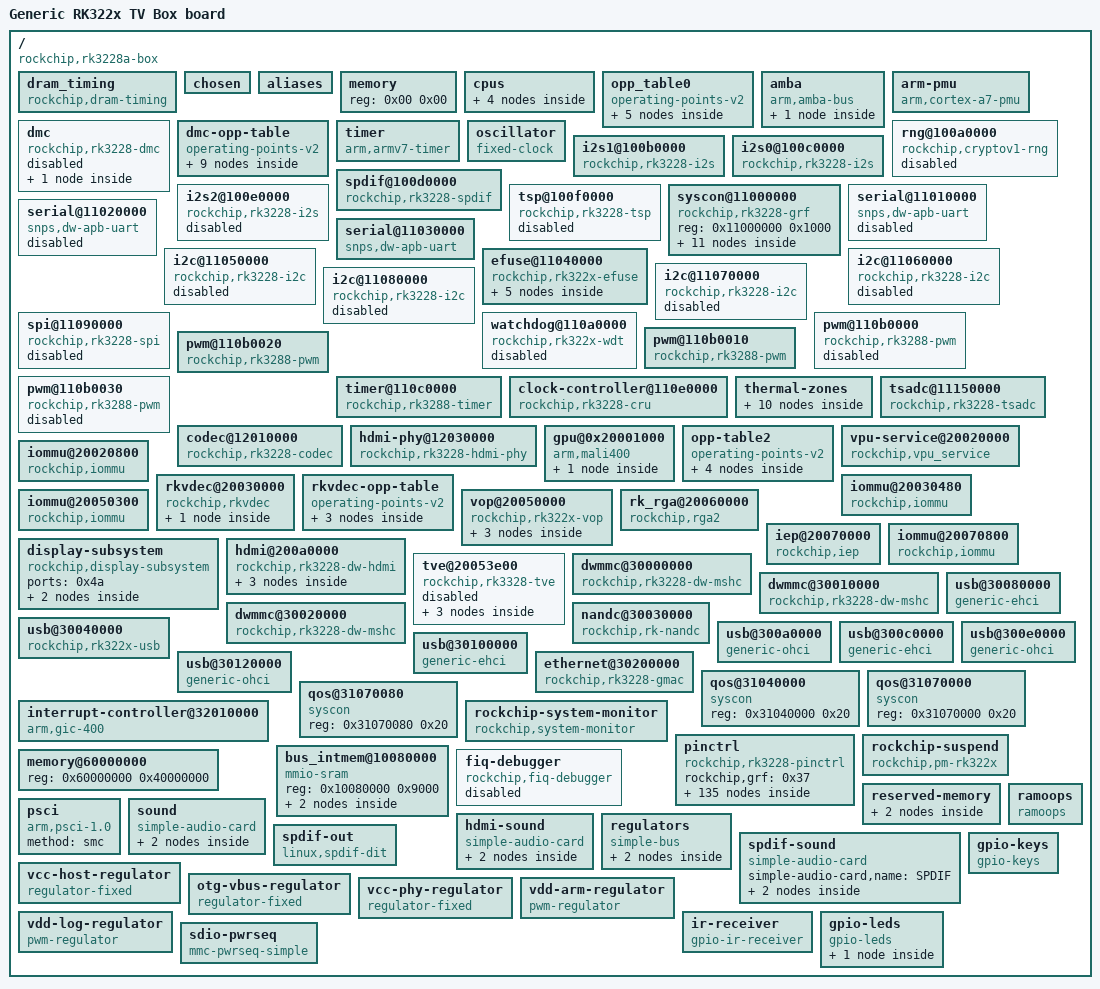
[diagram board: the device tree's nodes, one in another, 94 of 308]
/dts-v1/;

/ {
	#address-cells = <0x01>;
	#size-cells = <0x01>;
	interrupt-parent = <0x01>;
	compatible = "rockchip,rk3228a-box\0rockchip,rk3229";
	model = "Generic RK322x TV Box board";

	dram_timing {
		compatible = "rockchip,dram-timing";
		dram_spd_bin = <0x15>;
		sr_idle = <0x18>;
		pd_idle = <0x20>;
		dram_dll_disb_freq = <0x12c>;
		phy_dll_disb_freq = <0x190>;
		dram_odt_disb_freq = <0x14d>;
		phy_odt_disb_freq = <0x14d>;
		ddr3_drv = <0x00>;
		ddr3_odt = <0x40>;
		lpddr3_drv = <0x01>;
		lpddr3_odt = <0x03>;
		lpddr2_drv = <0x01>;
		phy_ddr3_clk_drv = <0x12>;
		phy_ddr3_cmd_drv = <0x12>;
		phy_ddr3_dqs_drv = <0x15>;
		phy_ddr3_odt = <0x02>;
		phy_lp23_clk_drv = <0x13>;
		phy_lp23_cmd_drv = <0x16>;
		phy_lp23_dqs_drv = <0x16>;
		phy_lp3_odt = <0x02>;
		phandle = <0x0b>;
	};

	chosen {
		stdout-path = "/serial@11030000";
		bootargs = "earlycon=uart8250,mmio32,0x11030000";
	};

	aliases {
		serial0 = "/serial@11010000";
		serial1 = "/serial@11020000";
		serial2 = "/serial@11030000";
		spi0 = "/spi@11090000";
	};

	memory {
		device_type = "memory";
		reg = <0x00 0x00>;
	};

	cpus {
		#address-cells = <0x01>;
		#size-cells = <0x00>;

		cpu@f00 {
			device_type = "cpu";
			compatible = "arm,cortex-a7";
			reg = <0xf00>;
			resets = <0x02 0x04>;
			operating-points-v2 = <0x03>;
			#cooling-cells = <0x02>;
			dynamic-power-coefficient = <0x7a>;
			clock-latency = <0x9c40>;
			clocks = <0x02 0x05>;
			enable-method = "psci";
			cpu-supply = <0x04>;
			phandle = <0x06>;
		};

		cpu@f01 {
			device_type = "cpu";
			compatible = "arm,cortex-a7";
			reg = <0xf01>;
			resets = <0x02 0x05>;
			operating-points-v2 = <0x03>;
			enable-method = "psci";
			cpu-supply = <0x04>;
			phandle = <0x07>;
		};

		cpu@f02 {
			device_type = "cpu";
			compatible = "arm,cortex-a7";
			reg = <0xf02>;
			resets = <0x02 0x06>;
			operating-points-v2 = <0x03>;
			enable-method = "psci";
			cpu-supply = <0x04>;
			phandle = <0x08>;
		};

		cpu@f03 {
			device_type = "cpu";
			compatible = "arm,cortex-a7";
			reg = <0xf03>;
			resets = <0x02 0x07>;
			operating-points-v2 = <0x03>;
			enable-method = "psci";
			cpu-supply = <0x04>;
			phandle = <0x09>;
		};
	};

	opp_table0 {
		compatible = "operating-points-v2";
		opp-shared;
		clocks = <0x02 0x01>;
		rockchip,max-volt = <0x149970>;
		rockchip,leakage-voltage-sel = <0x01 0x08 0x00 0x09 0xfe 0x01>;
		nvmem-cells = <0x05>;
		nvmem-cell-names = "cpu_leakage";
		phandle = <0x03>;

		opp-408000000 {
			opp-hz = <0x00 0x18519600>;
			opp-microvolt = <0xe7ef0 0xe7ef0 0x155cc0>;
			opp-microvolt-L0 = <0xe7ef0 0xe7ef0 0x155cc0>;
			opp-microvolt-L1 = <0xe7ef0 0xe7ef0 0x155cc0>;
			clock-latency-ns = <0x9c40>;
			opp-suspend;
		};

		opp-600000000 {
			opp-hz = <0x00 0x23c34600>;
			opp-microvolt = <0xee098 0xee098 0x155cc0>;
			opp-microvolt-L0 = <0xee098 0xee098 0x155cc0>;
			opp-microvolt-L1 = <0xee098 0xee098 0x155cc0>;
		};

		opp-816000000 {
			opp-hz = <0x00 0x30a32c00>;
			opp-microvolt = <0xf4240 0xf4240 0x155cc0>;
			opp-microvolt-L0 = <0xf4240 0xf4240 0x155cc0>;
			opp-microvolt-L1 = <0xf4240 0xf4240 0x155cc0>;
		};

		opp-1008000000 {
			opp-hz = <0x00 0x3c14dc00>;
			opp-microvolt = <0x11edd8 0x11edd8 0x155cc0>;
			opp-microvolt-L0 = <0x11edd8 0x11edd8 0x155cc0>;
			opp-microvolt-L1 = <0x112a88 0x112a88 0x155cc0>;
		};

		opp-1200000000 {
			opp-hz = <0x00 0x47868c00>;
			opp-microvolt = <0x137478 0x137478 0x155cc0>;
			opp-microvolt-L0 = <0x137478 0x137478 0x155cc0>;
			opp-microvolt-L1 = <0x12b128 0x12b128 0x155cc0>;
		};
	};

	amba {
		compatible = "arm,amba-bus";
		#address-cells = <0x01>;
		#size-cells = <0x01>;
		ranges;

		pdma@110f0000 {
			compatible = "arm,pl330\0arm,primecell";
			reg = <0x110f0000 0x4000>;
			interrupts = <0x00 0x00 0x04 0x00 0x01 0x04>;
			#dma-cells = <0x01>;
			clocks = <0x02 0xc2>;
			clock-names = "apb_pclk";
			peripherals-req-type-burst;
			phandle = <0x0e>;
		};
	};

	arm-pmu {
		compatible = "arm,cortex-a7-pmu";
		interrupts = <0x00 0x4c 0x04 0x00 0x4d 0x04 0x00 0x4e 0x04 0x00 0x4f 0x04>;
		interrupt-affinity = <0x06 0x07 0x08 0x09>;
	};

	dmc {
		compatible = "rockchip,rk3228-dmc\0rockchip,rk322x-dram";
		clocks = <0x02 0x90>;
		clock-names = "dmc_clk";
		operating-points-v2 = <0x0a>;
		system-status-freq = <0x01 0x927c0 0x10 0xa2990 0x10000 0xbfe50>;
		dram_freq = <0x2ed96880>;
		rockchip,dram_timing = <0x0b>;
		#cooling-cells = <0x02>;
		status = "disabled";
		center-supply = <0x0c>;
		phandle = <0x3b>;

		ddr_power_model {
			compatible = "ddr_power_model";
			dynamic-power-coefficient = <0x78>;
			static-power-coefficient = <0xc8>;
			ts = <0x7d00 0x125c 0xffffffb0 0x02>;
			thermal-zone = "soc-thermal";
			phandle = <0x78>;
		};
	};

	dmc-opp-table {
		compatible = "operating-points-v2";
		rockchip,leakage-voltage-sel = <0x01 0x05 0x00 0x06 0xfe 0x01>;
		nvmem-cells = <0x0d>;
		nvmem-cell-names = "ddr_leakage";
		phandle = <0x0a>;

		opp-300000000 {
			opp-hz = <0x00 0x11e1a300>;
			opp-microvolt = <0x100590>;
			opp-microvolt-L0 = <0x100590>;
			opp-microvolt-L1 = <0xf4240>;
		};

		opp-330000000 {
			opp-hz = <0x00 0x13ab6680>;
			opp-microvolt = <0x100590>;
			opp-microvolt-L0 = <0x100590>;
			opp-microvolt-L1 = <0xf4240>;
		};

		opp-400000000 {
			opp-hz = <0x00 0x17d78400>;
			opp-microvolt = <0x100590>;
			opp-microvolt-L0 = <0x100590>;
			opp-microvolt-L1 = <0xf4240>;
		};

		opp-528000000 {
			opp-hz = <0x00 0x1f78a400>;
			opp-microvolt = <0x100590>;
			opp-microvolt-L0 = <0x100590>;
			opp-microvolt-L1 = <0xf4240>;
		};

		opp-600000000 {
			opp-hz = <0x00 0x23c34600>;
			opp-microvolt = <0x10c8e0>;
			opp-microvolt-L0 = <0x10c8e0>;
			opp-microvolt-L1 = <0x100590>;
		};

		opp-666000000 {
			opp-hz = <0x00 0x27b25a80>;
			opp-microvolt = <0x118c30>;
			opp-microvolt-L0 = <0x118c30>;
			opp-microvolt-L1 = <0x10c8e0>;
		};

		opp-700000000 {
			opp-hz = <0x00 0x29b92700>;
			opp-microvolt = <0x118c30>;
			opp-microvolt-L0 = <0x118c30>;
			opp-microvolt-L1 = <0x10c8e0>;
		};

		opp-786000000 {
			opp-hz = <0x00 0x2ed96880>;
			opp-microvolt = <0x118c30>;
			opp-microvolt-L0 = <0x118c30>;
			opp-microvolt-L1 = <0x10c8e0>;
		};

		opp-800000000 {
			opp-hz = <0x00 0x2faf0800>;
			opp-microvolt = <0x118c30>;
			opp-microvolt-L0 = <0x118c30>;
			opp-microvolt-L1 = <0x10c8e0>;
		};
	};

	timer {
		compatible = "arm,armv7-timer";
		interrupts = <0x01 0x0d 0xf04 0x01 0x0e 0xf04 0x01 0x0b 0xf04 0x01 0x0a 0xf04>;
		clock-frequency = <0x16e3600>;
		arm,cpu-registers-not-fw-configured;
	};

	oscillator {
		compatible = "fixed-clock";
		clock-frequency = <0x16e3600>;
		clock-output-names = "xin24m";
		#clock-cells = <0x00>;
		phandle = <0x36>;
	};

	rng@100a0000 {
		compatible = "rockchip,cryptov1-rng";
		reg = <0x100a0000 0x4000>;
		clocks = <0x02 0x8a 0x02 0x1dd>;
		clock-names = "clk_crypto\0hclk_crypto";
		assigned-clocks = <0x02 0x8a 0x02 0x1dd>;
		assigned-clock-rates = <0x8f0d180 0x5f5e100>;
		resets = <0x02 0x35>;
		reset-names = "reset";
		status = "disabled";
		phandle = <0x79>;
	};

	i2s1@100b0000 {
		compatible = "rockchip,rk3228-i2s\0rockchip,rk3066-i2s";
		reg = <0x100b0000 0x4000>;
		interrupts = <0x00 0x1b 0x04>;
		#address-cells = <0x01>;
		#size-cells = <0x00>;
		clock-names = "i2s_clk\0i2s_hclk";
		clocks = <0x02 0x51 0x02 0x1bb>;
		dmas = <0x0e 0x0e 0x0e 0x0f>;
		dma-names = "tx\0rx";
		resets = <0x02 0x19>;
		reset-names = "reset-m";
		pinctrl-names = "default";
		pinctrl-0 = <0x0f>;
		status = "okay";
		#sound-dai-cells = <0x00>;
		phandle = <0x6a>;
	};

	i2s0@100c0000 {
		compatible = "rockchip,rk3228-i2s\0rockchip,rk3066-i2s";
		reg = <0x100c0000 0x4000>;
		interrupts = <0x00 0x1a 0x04>;
		#address-cells = <0x01>;
		#size-cells = <0x00>;
		clock-names = "i2s_clk\0i2s_hclk";
		clocks = <0x02 0x50 0x02 0x1ba>;
		dmas = <0x0e 0x0b 0x0e 0x0c>;
		dma-names = "tx\0rx";
		resets = <0x02 0x18>;
		reset-names = "reset-m";
		status = "okay";
		rockchip,bclk-fs = <0x80>;
		#sound-dai-cells = <0x00>;
		phandle = <0x6c>;
	};

	spdif@100d0000 {
		compatible = "rockchip,rk3228-spdif";
		reg = <0x100d0000 0x1000>;
		interrupts = <0x00 0x1d 0x04>;
		clocks = <0x02 0x53 0x02 0x1bd>;
		clock-names = "mclk\0hclk";
		dmas = <0x0e 0x0a>;
		#dma-cells = <0x01>;
		dma-names = "tx";
		pinctrl-names = "default";
		pinctrl-0 = <0x10>;
		status = "okay";
		#sound-dai-cells = <0x00>;
		phandle = <0x6e>;
	};

	i2s2@100e0000 {
		compatible = "rockchip,rk3228-i2s\0rockchip,rk3066-i2s";
		reg = <0x100e0000 0x4000>;
		interrupts = <0x00 0x1c 0x04>;
		#address-cells = <0x01>;
		#size-cells = <0x00>;
		clock-names = "i2s_clk\0i2s_hclk";
		clocks = <0x02 0x52 0x02 0x1bc>;
		dmas = <0x0e 0x00 0x0e 0x01>;
		dma-names = "tx\0rx";
		resets = <0x02 0x1a>;
		reset-names = "reset-m";
		status = "disabled";
		phandle = <0x7a>;
	};

	tsp@100f0000 {
		compatible = "rockchip,rk3228-tsp";
		reg = <0x100f0000 0x10000>;
		interrupts = <0x00 0x48 0x04>;
		interrupt-names = "irq_tsp";
		clocks = <0x02 0x8b 0x02 0x1db 0x02 0x8c>;
		clock-names = "clk_tsp\0hclk_tsp\0aclk_tsp";
		pinctrl-names = "default";
		pinctrl-0 = <0x11 0x12 0x13 0x14 0x15 0x16 0x17 0x18 0x19 0x1a 0x1b 0x1c>;
		status = "disabled";
		phandle = <0x7b>;
	};

	syscon@11000000 {
		compatible = "rockchip,rk3228-grf\0syscon\0simple-mfd";
		reg = <0x11000000 0x1000>;
		#address-cells = <0x01>;
		#size-cells = <0x01>;
		phandle = <0x37>;

		io-domains {
			compatible = "rockchip,rk322x-io-voltage-domain";
			status = "okay";
			vccio1-supply = <0x1d>;
			vccio2-supply = <0x1e>;
			vccio4-supply = <0x1d>;
			phandle = <0x7c>;
		};

		reboot-mode {
			compatible = "syscon-reboot-mode";
			offset = <0x5c8>;
			mode-normal = <0x5242c300>;
			mode-recovery = <0x5242c303>;
			mode-bootloader = <0x5242c309>;
			mode-loader = <0x5242c301>;
			mode-ums = <0x5242c30c>;
			phandle = <0x7d>;
		};

		usb2-phy@760 {
			compatible = "rockchip,rk3228-usb2phy";
			reg = <0x760 0x0c>;
			clocks = <0x02 0x8e>;
			clock-names = "phyclk";
			#clock-cells = <0x00>;
			clock-output-names = "usb480m_phy0";
			status = "okay";
			phandle = <0x5b>;

			otg-port {
				#phy-cells = <0x00>;
				interrupts = <0x00 0x3b 0x04 0x00 0x3c 0x04 0x00 0x3d 0x04>;
				interrupt-names = "otg-bvalid\0otg-id\0linestate";
				status = "okay";
				vbus-supply = <0x1f>;
				phandle = <0x5a>;
			};

			host-port {
				#phy-cells = <0x00>;
				interrupts = <0x00 0x3e 0x04>;
				interrupt-names = "linestate";
				status = "okay";
				phy-supply = <0x20>;
				phandle = <0x5c>;
			};
		};

		usb2-phy@800 {
			compatible = "rockchip,rk3228-usb2phy";
			reg = <0x800 0x0c>;
			clocks = <0x02 0x8f>;
			clock-names = "phyclk";
			#clock-cells = <0x00>;
			clock-output-names = "usb480m_phy1";
			status = "okay";
			phandle = <0x5d>;

			otg-port {
				#phy-cells = <0x00>;
				interrupts = <0x00 0x45 0x04>;
				interrupt-names = "linestate";
				status = "okay";
				phy-supply = <0x20>;
				phandle = <0x5f>;
			};

			host-port {
				#phy-cells = <0x00>;
				interrupts = <0x00 0x44 0x04>;
				interrupt-names = "linestate";
				status = "okay";
				phy-supply = <0x20>;
				phandle = <0x5e>;
			};
		};

		power-controller {
			compatible = "rockchip,rk3228-power-controller";
			#power-domain-cells = <0x01>;
			#address-cells = <0x01>;
			#size-cells = <0x00>;
			status = "okay";
			phandle = <0x42>;

			pd_vpu@6 {
				reg = <0x06>;
				clocks = <0x02 0xca 0x02 0x1d0>;
				pm_qos = <0x21>;
			};

			pd_rkvdec@7 {
				reg = <0x07>;
				clocks = <0x02 0xcb 0x02 0x1d1 0x02 0x85 0x02 0x86>;
				pm_qos = <0x22 0x23>;
			};
		};
	};

	serial@11010000 {
		compatible = "snps,dw-apb-uart";
		reg = <0x11010000 0x100>;
		interrupts = <0x00 0x37 0x04>;
		clock-frequency = <0x16e3600>;
		clocks = <0x02 0x4d 0x02 0x155>;
		clock-names = "baudclk\0apb_pclk";
		pinctrl-names = "default";
		pinctrl-0 = <0x24 0x25 0x26>;
		reg-shift = <0x02>;
		reg-io-width = <0x04>;
		status = "disabled";
		phandle = <0x7e>;
	};

	serial@11020000 {
		compatible = "snps,dw-apb-uart";
		reg = <0x11020000 0x100>;
		interrupts = <0x00 0x38 0x04>;
		clock-frequency = <0x16e3600>;
		clocks = <0x02 0x4e 0x02 0x156>;
		clock-names = "baudclk\0apb_pclk";
		pinctrl-names = "default";
		pinctrl-0 = <0x27>;
		reg-shift = <0x02>;
		reg-io-width = <0x04>;
		status = "disabled";
		phandle = <0x7f>;
	};

	serial@11030000 {
		compatible = "snps,dw-apb-uart";
		reg = <0x11030000 0x100>;
		interrupts = <0x00 0x39 0x04>;
		clock-frequency = <0x16e3600>;
		clocks = <0x02 0x4f 0x02 0x157>;
		clock-names = "baudclk\0apb_pclk";
		pinctrl-names = "default";
		pinctrl-0 = <0x28>;
		reg-shift = <0x02>;
		reg-io-width = <0x04>;
		status = "okay";
		phandle = <0x80>;
	};

	efuse@11040000 {
		compatible = "rockchip,rk322x-efuse";
		reg = <0x11040000 0x20>;
		#address-cells = <0x01>;
		#size-cells = <0x01>;
		clocks = <0x02 0x147>;
		clock-names = "pclk_efuse";
		phandle = <0x81>;

		id@7 {
			reg = <0x07 0x10>;
			phandle = <0x82>;
		};

		cpu_leakage@17 {
			reg = <0x17 0x01>;
			phandle = <0x05>;
		};

		logic-leakage@19 {
			reg = <0x19 0x01>;
			phandle = <0x0d>;
		};

		hdmi_phy_flag@1d {
			reg = <0x1d 0x01>;
			bits = <0x01 0x01>;
			phandle = <0x40>;
		};

		tve_dac@1d {
			reg = <0x1d 0x01>;
			bits = <0x03 0x05>;
			phandle = <0x51>;
		};
	};

	i2c@11050000 {
		compatible = "rockchip,rk3228-i2c";
		reg = <0x11050000 0x1000>;
		interrupts = <0x00 0x24 0x04>;
		#address-cells = <0x01>;
		#size-cells = <0x00>;
		clock-names = "i2c";
		clocks = <0x02 0x14c>;
		pinctrl-names = "default";
		pinctrl-0 = <0x29>;
		status = "disabled";
		phandle = <0x83>;
	};

	i2c@11060000 {
		compatible = "rockchip,rk3228-i2c";
		reg = <0x11060000 0x1000>;
		interrupts = <0x00 0x25 0x04>;
		#address-cells = <0x01>;
		#size-cells = <0x00>;
		clock-names = "i2c";
		clocks = <0x02 0x14d>;
		pinctrl-names = "default";
		pinctrl-0 = <0x2a>;
		status = "disabled";
		phandle = <0x84>;
	};

	i2c@11070000 {
		compatible = "rockchip,rk3228-i2c";
		reg = <0x11070000 0x1000>;
		interrupts = <0x00 0x26 0x04>;
		#address-cells = <0x01>;
		#size-cells = <0x00>;
		clock-names = "i2c";
		clocks = <0x02 0x14e>;
		pinctrl-names = "default";
		pinctrl-0 = <0x2b>;
		status = "disabled";
		phandle = <0x85>;
	};

	i2c@11080000 {
		compatible = "rockchip,rk3228-i2c";
		reg = <0x11080000 0x1000>;
		interrupts = <0x00 0x27 0x04>;
		#address-cells = <0x01>;
		#size-cells = <0x00>;
		clock-names = "i2c";
		clocks = <0x02 0x14f>;
		pinctrl-names = "default";
		pinctrl-0 = <0x2c>;
		status = "disabled";
		phandle = <0x86>;
	};

	spi@11090000 {
		compatible = "rockchip,rk3228-spi";
		reg = <0x11090000 0x1000>;
		interrupts = <0x00 0x31 0x04>;
		#address-cells = <0x01>;
		#size-cells = <0x00>;
		pinctrl-names = "default";
		pinctrl-0 = <0x2d 0x2e 0x2f 0x30 0x31>;
		clocks = <0x02 0x41 0x02 0x152>;
		clock-names = "spiclk\0apb_pclk";
		status = "disabled";
		phandle = <0x87>;
	};

	watchdog@110a0000 {
		compatible = "rockchip,rk322x-wdt\0snps,dw-wdt";
		reg = <0x110a0000 0x100>;
		clocks = <0x02 0x162>;
		interrupts = <0x00 0x28 0x04>;
		status = "disabled";
		phandle = <0x88>;
	};

	pwm@110b0000 {
		compatible = "rockchip,rk3288-pwm";
		reg = <0x110b0000 0x10>;
		#pwm-cells = <0x03>;
		clocks = <0x02 0x15e>;
		clock-names = "pwm";
		pinctrl-names = "active";
		pinctrl-0 = <0x32>;
		status = "disabled";
		phandle = <0x89>;
	};

	pwm@110b0010 {
		compatible = "rockchip,rk3288-pwm";
		reg = <0x110b0010 0x10>;
		#pwm-cells = <0x03>;
		clocks = <0x02 0x15e>;
		clock-names = "pwm";
		pinctrl-names = "active";
		pinctrl-0 = <0x33>;
		status = "okay";
		phandle = <0x73>;
	};

	pwm@110b0020 {
		compatible = "rockchip,rk3288-pwm";
		reg = <0x110b0020 0x10>;
		#pwm-cells = <0x03>;
		clocks = <0x02 0x15e>;
		clock-names = "pwm";
		pinctrl-names = "active";
		pinctrl-0 = <0x34>;
		status = "okay";
		phandle = <0x74>;
	};

	pwm@110b0030 {
		compatible = "rockchip,rk3288-pwm";
		reg = <0x110b0030 0x10>;
		interrupts = <0x00 0x32 0x04>;
		#pwm-cells = <0x03>;
		clocks = <0x02 0x15e>;
		clock-names = "pwm";
		pinctrl-names = "active";
		pinctrl-0 = <0x35>;
		status = "disabled";
		phandle = <0x8a>;
	};

	timer@110c0000 {
		compatible = "rockchip,rk3288-timer";
		reg = <0x110c0000 0x20>;
		interrupts = <0x00 0x2b 0x04>;
		clocks = <0x36 0x02 0x161>;
		clock-names = "timer\0pclk";
		phandle = <0x8b>;
	};

	clock-controller@110e0000 {
		compatible = "rockchip,rk3228-cru";
		reg = <0x110e0000 0x1000>;
		rockchip,grf = <0x37>;
		#clock-cells = <0x01>;
		#reset-cells = <0x01>;
		assigned-clocks = <0x02 0x04 0x02 0x05 0x02 0x03 0x02 0xd2 0x02 0x1de 0x02 0x16b 0x02 0xc3 0x02 0x1cc 0x02 0x162 0x02 0xd3>;
		assigned-clock-rates = <0x47868c00 0x30a32c00 0x1dcd6500 0x8f0d180 0x8f0d180 0x47868c0 0x8f0d180 0x8f0d180 0x47868c0 0x17d78400>;
		phandle = <0x02>;
	};

	thermal-zones {
		phandle = <0x8c>;

		soc-thermal {
			polling-delay-passive = <0x64>;
			polling-delay = <0x1388>;
			sustainable-power = <0x4b0>;
			thermal-sensors = <0x38 0x00>;
			phandle = <0x8d>;

			trips {

				trip-point@0 {
					temperature = <0x15f90>;
					hysteresis = <0x7d0>;
					type = "passive";
					phandle = <0x8e>;
				};

				trip-point@1 {
					temperature = <0x19a28>;
					hysteresis = <0x7d0>;
					type = "passive";
					phandle = <0x39>;
				};

				soc-crit {
					temperature = <0x1c138>;
					hysteresis = <0x7d0>;
					type = "critical";
					phandle = <0x8f>;
				};
			};

			cooling-maps {

				map0 {
					trip = <0x39>;
					cooling-device = <0x06 0xffffffff 0xffffffff>;
					contribution = <0x400>;
				};

				map1 {
					trip = <0x39>;
					cooling-device = <0x3a 0xffffffff 0xffffffff>;
					contribution = <0x400>;
				};

				map2 {
					trip = <0x39>;
					cooling-device = <0x3b 0xffffffff 0xffffffff>;
					contribution = <0x400>;
				};

				map3 {
					trip = <0x39>;
					cooling-device = <0x3c 0xffffffff 0xffffffff>;
					contribution = <0x400>;
				};
			};
		};
	};

	tsadc@11150000 {
		compatible = "rockchip,rk3228-tsadc";
		reg = <0x11150000 0x100>;
		interrupts = <0x00 0x3a 0x04>;
		clocks = <0x02 0x48 0x02 0x158>;
		clock-names = "tsadc\0apb_pclk";
		assigned-clocks = <0x02 0x48>;
		assigned-clock-rates = <0x8000>;
		resets = <0x02 0x57>;
		reset-names = "tsadc-apb";
		pinctrl-names = "gpio\0otpout";
		pinctrl-0 = <0x3d>;
		pinctrl-1 = <0x3e>;
		#thermal-sensor-cells = <0x00>;
		rockchip,hw-tshut-temp = <0x1d4c0>;
		status = "okay";
		rockchip,hw-tshut-mode = <0x00>;
		rockchip,hw-tshut-polarity = <0x01>;
		rockchip,grf = <0x37>;
		phandle = <0x38>;
	};

	codec@12010000 {
		compatible = "rockchip,rk3228-codec";
		reg = <0x12010000 0x1000>;
		clocks = <0x02 0x71 0x02 0x170 0x02 0x51>;
		clock-names = "mclk\0pclk\0sclk";
		spk-en-gpio = <0x3f 0x03 0x00>;
		status = "okay";
		#sound-dai-cells = <0x00>;
		phandle = <0x6b>;
	};

	hdmi-phy@12030000 {
		compatible = "rockchip,rk3228-hdmi-phy";
		reg = <0x12030000 0x10000>;
		#phy-cells = <0x00>;
		clocks = <0x02 0x16d 0x36>;
		clock-names = "sysclk\0refclk";
		#clock-cells = <0x00>;
		clock-output-names = "hdmiphy_phy";
		nvmem-cells = <0x40>;
		nvmem-cell-names = "hdmi_phy_flag";
		status = "okay";
		phandle = <0x50>;
	};

	gpu@0x20001000 {
		compatible = "arm,mali400";
		reg = <0x20001000 0x200 0x20000000 0x100 0x20003000 0x100 0x20008000 0x1100 0x20004000 0x100 0x2000a000 0x1100 0x20005000 0x100>;
		reg-names = "Mali_L2\0Mali_GP\0Mali_GP_MMU\0Mali_PP0\0Mali_PP0_MMU\0Mali_PP1\0Mali_PP1_MMU";
		interrupts = <0x00 0x06 0x04 0x00 0x05 0x04 0x00 0x04 0x04 0x00 0x05 0x04 0x00 0x04 0x04 0x00 0x05 0x04>;
		interrupt-names = "Mali_GP_IRQ\0Mali_GP_MMU_IRQ\0Mali_PP0_IRQ\0Mali_PP0_MMU_IRQ\0Mali_PP1_IRQ\0Mali_PP1_MMU_IRQ";
		clocks = <0x02 0xd5>;
		#cooling-cells = <0x02>;
		clock-names = "clk_mali";
		operating-points-v2 = <0x41>;
		status = "okay";
		mali-supply = <0x0c>;
		phandle = <0x3a>;

		power_model {
			compatible = "arm,mali-simple-power-model";
			voltage = <0x384>;
			frequency = <0x1f4>;
			static-power = <0x12c>;
			dynamic-power = <0x18c>;
			ts = <0x7d00 0x125c 0xffffffb0 0x02>;
			thermal-zone = "soc-thermal";
			phandle = <0x90>;
		};
	};

	opp-table2 {
		compatible = "operating-points-v2";
		rockchip,leakage-voltage-sel = <0x01 0x05 0x00 0x06 0xfe 0x01>;
		nvmem-cells = <0x0d>;
		nvmem-cell-names = "gpu_leakage";
		phandle = <0x41>;

		opp-200000000 {
			opp-hz = <0x00 0xbebc200>;
			opp-microvolt = <0x106738>;
			opp-microvolt-L0 = <0x106738>;
			opp-microvolt-L1 = <0x100590>;
		};

		opp-300000000 {
			opp-hz = <0x00 0x11e1a300>;
			opp-microvolt = <0x106738>;
			opp-microvolt-L0 = <0x106738>;
			opp-microvolt-L1 = <0x100590>;
		};

		opp-500000000 {
			opp-hz = <0x00 0x1dcd6500>;
			opp-microvolt = <0x118c30>;
			opp-microvolt-L0 = <0x118c30>;
			opp-microvolt-L1 = <0x10c8e0>;
		};

		opp-400000000 {
			opp-hz = <0x00 0x17d78400>;
			opp-microvolt = <0x118c30>;
			opp-microvolt-L0 = <0x118c30>;
			opp-microvolt-L1 = <0x10c8e0>;
		};
	};

	vpu-service@20020000 {
		compatible = "rockchip,vpu_service";
		reg = <0x20020000 0x800>;
		interrupts = <0x00 0x09 0x04 0x00 0x0b 0x04>;
		interrupt-names = "irq_dec\0irq_enc";
		resets = <0x02 0x70 0x02 0x71>;
		reset-names = "video_a\0video_h";
		clocks = <0x02 0xca 0x02 0x1d0>;
		clock-names = "aclk_vcodec\0hclk_vcodec";
		power-domains = <0x42 0x06>;
		rockchip,grf = <0x37>;
		iommus = <0x43>;
		allocator = <0x01>;
		status = "okay";
		phandle = <0x91>;
	};

	iommu@20020800 {
		compatible = "rockchip,iommu";
		reg = <0x20020800 0x40>;
		interrupts = <0x00 0x0a 0x04>;
		interrupt-names = "vpu_mmu";
		clock-names = "aclk\0hclk";
		clocks = <0x02 0xca 0x02 0x1d0>;
		power-domains = <0x42 0x06>;
		#iommu-cells = <0x00>;
		status = "okay";
		phandle = <0x43>;
	};

	rkvdec@20030000 {
		compatible = "rockchip,rkvdec";
		reg = <0x20030000 0x400>;
		interrupts = <0x00 0x07 0x04>;
		interrupt-names = "irq_dec";
		clocks = <0x02 0xcb 0x02 0x1d1 0x02 0x85 0x02 0x86>;
		clock-names = "aclk_vcodec\0hclk_vcodec\0clk_cabac\0clk_core";
		resets = <0x02 0x76 0x02 0x78 0x02 0x77 0x02 0x79 0x02 0x7b 0x02 0x7a>;
		reset-names = "video_a\0video_h\0niu_a\0niu_h\0video_cabac\0video_core";
		power-domains = <0x42 0x07>;
		operating-points-v2 = <0x44>;
		#cooling-cells = <0x02>;
		rockchip,grf = <0x37>;
		iommus = <0x45>;
		allocator = <0x01>;
		status = "okay";
		vcodec-supply = <0x0c>;
		phandle = <0x3c>;

		vcodec_power_model {
			compatible = "vcodec_power_model";
			dynamic-power-coefficient = <0x78>;
			static-power-coefficient = <0xc8>;
			ts = <0x7d00 0x125c 0xffffffb0 0x02>;
			thermal-zone = "soc-thermal";
			phandle = <0x92>;
		};
	};

	rkvdec-opp-table {
		compatible = "operating-points-v2";
		rockchip,leakage-voltage-sel = <0x01 0x05 0x00 0x06 0xfe 0x01>;
		nvmem-cells = <0x0d>;
		nvmem-cell-names = "rkvdec_leakage";
		phandle = <0x44>;

		opp-100000000 {
			opp-hz = <0x00 0x5f5e100>;
			opp-microvolt = <0x100590>;
			opp-microvolt-L0 = <0x100590>;
			opp-microvolt-L1 = <0xf4240>;
		};

		opp-200000000 {
			opp-hz = <0x00 0xbebc200>;
			opp-microvolt = <0x100590>;
			opp-microvolt-L0 = <0x100590>;
			opp-microvolt-L1 = <0xf4240>;
		};

		opp-500000000 {
			opp-hz = <0x00 0x1dcd6500>;
			opp-microvolt = <0x100590>;
			opp-microvolt-L0 = <0x100590>;
			opp-microvolt-L1 = <0xf4240>;
		};
	};

	iommu@20030480 {
		compatible = "rockchip,iommu";
		reg = <0x20030480 0x40 0x200304c0 0x40>;
		interrupts = <0x00 0x08 0x04>;
		interrupt-names = "rkvdec_mmu";
		clocks = <0x02 0xcb 0x02 0x1d1>;
		clock-names = "aclk\0hclk";
		power-domains = <0x42 0x07>;
		#iommu-cells = <0x00>;
		status = "okay";
		phandle = <0x45>;
	};

	vop@20050000 {
		compatible = "rockchip,rk322x-vop";
		reg = <0x20050000 0x1ffc>;
		reg-names = "regs";
		interrupts = <0x00 0x20 0x04>;
		clocks = <0x02 0xd3 0x02 0xbe 0x02 0x1c4>;
		clock-names = "aclk_vop\0dclk_vop\0hclk_vop";
		resets = <0x02 0x64 0x02 0x65 0x02 0x66>;
		reset-names = "axi\0ahb\0dclk";
		iommus = <0x46>;
		status = "okay";
		assigned-clocks = <0x02 0xbe>;
		assigned-clock-parents = <0x02 0xc0>;
		rockchip,grf = <0x37>;
		phandle = <0x93>;

		port {
			#address-cells = <0x01>;
			#size-cells = <0x00>;
			phandle = <0x4a>;

			endpoint@0 {
				reg = <0x00>;
				remote-endpoint = <0x47>;
				phandle = <0x4b>;
			};

			endpoint@1 {
				reg = <0x01>;
				remote-endpoint = <0x48>;
				phandle = <0x4c>;
			};
		};
	};

	iommu@20050300 {
		compatible = "rockchip,iommu";
		reg = <0x20053f00 0x100>;
		interrupts = <0x00 0x20 0x04>;
		interrupt-names = "vop_mmu";
		clocks = <0x02 0xd3 0x02 0x1c4>;
		clock-names = "aclk\0hclk";
		#iommu-cells = <0x00>;
		status = "okay";
		phandle = <0x46>;
	};

	rk_rga@20060000 {
		compatible = "rockchip,rga2";
		reg = <0x20060000 0x1000>;
		interrupts = <0x00 0x21 0x04>;
		clocks = <0x02 0xcd 0x02 0x1d3 0x02 0x87>;
		clock-names = "aclk_rga\0hclk_rga\0clk_rga";
		dma-coherent;
		status = "okay";
		phandle = <0x94>;
	};

	iep@20070000 {
		compatible = "rockchip,iep";
		iommu_enabled = <0x01>;
		iommus = <0x49>;
		reg = <0x20070000 0x800>;
		interrupts = <0x00 0x1f 0x04>;
		clocks = <0x02 0xcc 0x02 0x1d4>;
		clock-names = "aclk_iep\0hclk_iep";
		version = <0x03>;
		allocator = <0x01>;
		status = "okay";
		phandle = <0x95>;
	};

	iommu@20070800 {
		compatible = "rockchip,iommu";
		reg = <0x20070800 0x40>;
		interrupts = <0x00 0x1f 0x04>;
		interrupt-names = "iep_mmu";
		#iommu-cells = <0x00>;
		status = "okay";
		phandle = <0x49>;
	};

	display-subsystem {
		compatible = "rockchip,display-subsystem";
		ports = <0x4a>;
		status = "okay";
		phandle = <0x96>;

		route-hdmi {
			status = "okay";
			connect = <0x4b>;
			phandle = <0x97>;
		};

		route-tve {
			status = "disabled";
			connect = <0x4c>;
			phandle = <0x98>;
		};
	};

	hdmi@200a0000 {
		compatible = "rockchip,rk3228-dw-hdmi";
		reg = <0x200a0000 0x20000>;
		reg-io-width = <0x04>;
		interrupts = <0x00 0x23 0x04 0x00 0x47 0x04>;
		clocks = <0x02 0x7b 0x02 0x16c 0x02 0x89>;
		clock-names = "isfr\0iahb\0cec";
		pinctrl-names = "default";
		pinctrl-0 = <0x4d 0x4e 0x4f>;
		resets = <0x02 0x60>;
		reset-names = "hdmi";
		phys = <0x50>;
		phy-names = "hdmi_phy";
		rockchip,grf = <0x37>;
		status = "okay";
		#sound-dai-cells = <0x00>;
		ddc-i2c-scl-high-time-ns = <0x2599>;
		ddc-i2c-scl-low-time-ns = <0x2710>;
		phandle = <0x6d>;

		ports {

			port {
				#address-cells = <0x01>;
				#size-cells = <0x00>;
				phandle = <0x99>;

				endpoint@0 {
					reg = <0x00>;
					remote-endpoint = <0x4b>;
					phandle = <0x47>;
				};
			};
		};
	};

	tve@20053e00 {
		compatible = "rockchip,rk3328-tve";
		reg = <0x20053e00 0x100 0x12020000 0x10000>;
		rockchip,saturation = <0x305b46>;
		rockchip,brightcontrast = <0x9900>;
		rockchip,adjtiming = <0xd6c00880>;
		rockchip,lumafilter0 = <0x2ff0001>;
		rockchip,lumafilter1 = <0xf40200fe>;
		rockchip,lumafilter2 = <0xf332d910>;
		rockchip,daclevel = <0x15>;
		rockchip,dac1level = <0x07>;
		nvmem-cells = <0x51>;
		nvmem-cell-names = "tve_dac_adj";
		status = "disabled";
		phandle = <0x9a>;

		ports {

			port {
				#address-cells = <0x01>;
				#size-cells = <0x00>;
				phandle = <0x9b>;

				endpoint@0 {
					reg = <0x00>;
					remote-endpoint = <0x4c>;
					phandle = <0x48>;
				};
			};
		};
	};

	dwmmc@30000000 {
		compatible = "rockchip,rk3228-dw-mshc\0rockchip,rk3288-dw-mshc";
		reg = <0x30000000 0x4000>;
		interrupts = <0x00 0x0c 0x04>;
		clocks = <0x02 0x1c8 0x02 0x44 0x02 0x72 0x02 0x76>;
		clock-names = "biu\0ciu\0ciu-drive\0ciu-sample";
		fifo-depth = <0x100>;
		pinctrl-names = "default";
		pinctrl-0 = <0x52 0x53 0x54 0x55>;
		cd-gpios = <0x3f 0x11 0x01>;
		status = "okay";
		bus-width = <0x04>;
		cap-sd-highspeed;
		card-detect-delay = <0xc8>;
		disable-wp;
		max-frequency = <0x8f0d180>;
		num-slots = <0x01>;
		supports-sd;
		cd-debounce-delay-ms = <0x1f4>;
		phandle = <0x9c>;
	};

	dwmmc@30010000 {
		compatible = "rockchip,rk3228-dw-mshc\0rockchip,rk3288-dw-mshc";
		reg = <0x30010000 0x4000>;
		interrupts = <0x00 0x0d 0x04>;
		clocks = <0x02 0x1c9 0x02 0x45 0x02 0x73 0x02 0x77>;
		clock-names = "biu\0ciu\0ciu-drive\0ciu-sample";
		fifo-depth = <0x100>;
		pinctrl-names = "default";
		pinctrl-0 = <0x56 0x57 0x58>;
		status = "okay";
		bus-width = <0x04>;
		cap-mmc-highspeed;
		cap-sd-highspeed;
		cap-sdio-irq;
		non-removable;
		ignore-pm-notify;
		keep-power-in-suspend;
		max-frequency = <0x8f0d180>;
		supports-sdio;
		mmc-pwrseq = <0x59>;
		phandle = <0x9d>;
	};

	dwmmc@30020000 {
		compatible = "rockchip,rk3228-dw-mshc\0rockchip,rk3288-dw-mshc";
		reg = <0x30020000 0x4000>;
		interrupts = <0x00 0x0e 0x04>;
		clock-frequency = <0x2faf080>;
		clocks = <0x02 0x1cb 0x02 0x47 0x02 0x75 0x02 0x79>;
		clock-names = "biu\0ciu\0ciu-drive\0ciu-sample";
		bus-width = <0x08>;
		num-slots = <0x01>;
		fifo-depth = <0x100>;
		status = "okay";
		broken-cd;
		cap-mmc-highspeed;
		supports-emmc;
		disable-wp;
		non-removable;
		max-frequency = <0x8f0d180>;
		phandle = <0x9e>;
	};

	nandc@30030000 {
		compatible = "rockchip,rk-nandc";
		reg = <0x30030000 0x4000>;
		interrupts = <0x00 0x0f 0x04>;
		nandc_id = <0x00>;
		clocks = <0x02 0x43 0x02 0x1c5>;
		clock-names = "clk_nandc\0hclk_nandc";
		status = "okay";
		phandle = <0x9f>;
	};

	usb@30040000 {
		compatible = "rockchip,rk322x-usb\0rockchip,rk3066-usb\0snps,dwc2";
		reg = <0x30040000 0x40000>;
		interrupts = <0x00 0x17 0x04>;
		clocks = <0x02 0x1da>;
		clock-names = "otg";
		dr_mode = "host";
		g-np-tx-fifo-size = <0x10>;
		g-rx-fifo-size = <0x118>;
		g-tx-fifo-size = <0x100 0x80 0x80 0x40 0x20 0x10>;
		g-use-dma;
		phys = <0x5a>;
		phy-names = "usb2-phy";
		status = "okay";
		phandle = <0xa0>;
	};

	usb@30080000 {
		compatible = "generic-ehci";
		reg = <0x30080000 0x20000>;
		interrupts = <0x00 0x10 0x04>;
		clocks = <0x02 0x1d7 0x5b>;
		clock-names = "usbhost\0utmi";
		phys = <0x5c>;
		phy-names = "usb";
		status = "okay";
		phandle = <0xa1>;
	};

	usb@300a0000 {
		compatible = "generic-ohci";
		reg = <0x300a0000 0x20000>;
		interrupts = <0x00 0x11 0x04>;
		clocks = <0x02 0x1d7 0x5b>;
		clock-names = "usbhost\0utmi";
		phys = <0x5c>;
		phy-names = "usb";
		status = "okay";
		phandle = <0xa2>;
	};

	usb@300c0000 {
		compatible = "generic-ehci";
		reg = <0x300c0000 0x20000>;
		interrupts = <0x00 0x13 0x04>;
		clocks = <0x02 0x1d8 0x5d>;
		clock-names = "usbhost\0utmi";
		phys = <0x5e>;
		phy-names = "usb";
		status = "okay";
		phandle = <0xa3>;
	};

	usb@300e0000 {
		compatible = "generic-ohci";
		reg = <0x300e0000 0x20000>;
		interrupts = <0x00 0x14 0x04>;
		clocks = <0x02 0x1d8 0x5d>;
		clock-names = "usbhost\0utmi";
		phys = <0x5e>;
		phy-names = "usb";
		status = "okay";
		phandle = <0xa4>;
	};

	usb@30100000 {
		compatible = "generic-ehci";
		reg = <0x30100000 0x20000>;
		interrupts = <0x00 0x42 0x04>;
		clocks = <0x02 0x1d9 0x5d>;
		phys = <0x5f>;
		phy-names = "usb";
		clock-names = "usbhost\0utmi";
		status = "okay";
		phandle = <0xa5>;
	};

	usb@30120000 {
		compatible = "generic-ohci";
		reg = <0x30120000 0x20000>;
		interrupts = <0x00 0x43 0x04>;
		clocks = <0x02 0x1d9 0x5d>;
		clock-names = "usbhost\0utmi";
		phys = <0x5f>;
		phy-names = "usb";
		status = "okay";
		phandle = <0xa6>;
	};

	ethernet@30200000 {
		compatible = "rockchip,rk3228-gmac";
		reg = <0x30200000 0x10000>;
		interrupts = <0x00 0x18 0x04>;
		interrupt-names = "macirq";
		clocks = <0x02 0x7e 0x02 0x81 0x02 0x82 0x02 0x80 0x02 0x7f 0x02 0xd4 0x02 0x16f 0x02 0x83>;
		clock-names = "stmmaceth\0mac_clk_rx\0mac_clk_tx\0clk_mac_ref\0clk_mac_refout\0aclk_mac\0pclk_mac\0clk_macphy";
		resets = <0x02 0x38 0x02 0x3f>;
		reset-names = "stmmaceth\0mac-phy";
		rockchip,grf = <0x37>;
		status = "okay";
		assigned-clocks = <0x02 0x7c>;
		assigned-clock-rates = <0x2faf080>;
		clock_in_out = "output";
		phy-supply = <0x60>;
		phy-mode = "rmii";
		phy-is-integrated;
		tx_delay = <0x30>;
		rx_delay = <0x10>;
		pinctrl-names = "default";
		pinctrl-0 = <0x61>;
		snps,reset-gpio = <0x62 0x18 0x01>;
		snps,reset-active-low;
		phandle = <0xa7>;
	};

	qos@31040000 {
		compatible = "syscon";
		reg = <0x31040000 0x20>;
		phandle = <0x21>;
	};

	qos@31070000 {
		compatible = "syscon";
		reg = <0x31070000 0x20>;
		phandle = <0x22>;
	};

	qos@31070080 {
		compatible = "syscon";
		reg = <0x31070080 0x20>;
		phandle = <0x23>;
	};

	interrupt-controller@32010000 {
		compatible = "arm,gic-400";
		interrupt-controller;
		#interrupt-cells = <0x03>;
		#address-cells = <0x00>;
		reg = <0x32011000 0x1000 0x32012000 0x2000 0x32014000 0x2000 0x32016000 0x2000>;
		interrupts = <0x01 0x09 0xf04>;
		phandle = <0x01>;
	};

	rockchip-system-monitor {
		compatible = "rockchip,system-monitor";
		phandle = <0xa8>;
	};

	pinctrl {
		compatible = "rockchip,rk3228-pinctrl";
		rockchip,grf = <0x37>;
		#address-cells = <0x01>;
		#size-cells = <0x01>;
		ranges;
		phandle = <0xa9>;

		gpio0@11110000 {
			compatible = "rockchip,gpio-bank";
			reg = <0x11110000 0x100>;
			interrupts = <0x00 0x33 0x04>;
			clocks = <0x02 0x140>;
			gpio-controller;
			#gpio-cells = <0x02>;
			interrupt-controller;
			#interrupt-cells = <0x02>;
			phandle = <0xaa>;
		};

		gpio1@11120000 {
			compatible = "rockchip,gpio-bank";
			reg = <0x11120000 0x100>;
			interrupts = <0x00 0x34 0x04>;
			clocks = <0x02 0x141>;
			gpio-controller;
			#gpio-cells = <0x02>;
			interrupt-controller;
			#interrupt-cells = <0x02>;
			phandle = <0x3f>;
		};

		gpio2@11130000 {
			compatible = "rockchip,gpio-bank";
			reg = <0x11130000 0x100>;
			interrupts = <0x00 0x35 0x04>;
			clocks = <0x02 0x142>;
			gpio-controller;
			#gpio-cells = <0x02>;
			interrupt-controller;
			#interrupt-cells = <0x02>;
			phandle = <0x62>;
		};

		gpio3@11140000 {
			compatible = "rockchip,gpio-bank";
			reg = <0x11140000 0x100>;
			interrupts = <0x00 0x36 0x04>;
			clocks = <0x02 0x143>;
			gpio-controller;
			#gpio-cells = <0x02>;
			interrupt-controller;
			#interrupt-cells = <0x02>;
			phandle = <0x70>;
		};

		pcfg-pull-up {
			bias-pull-up;
			phandle = <0x64>;
		};

		pcfg-pull-down {
			bias-pull-down;
			phandle = <0x63>;
		};

		pcfg-pull-none {
			bias-disable;
			phandle = <0x65>;
		};

		pcfg-pull-none-drv-12ma {
			drive-strength = <0x0c>;
			phandle = <0x68>;
		};

		sdmmc {

			sdmmc-clk {
				rockchip,pins = <0x01 0x10 0x01 0x63>;
				phandle = <0x53>;
			};

			sdmmc-cmd {
				rockchip,pins = <0x01 0x0f 0x01 0x64>;
				phandle = <0x54>;
			};

			sdmmc-bus4 {
				rockchip,pins = <0x01 0x12 0x01 0x64 0x01 0x13 0x01 0x64 0x01 0x14 0x01 0x64 0x01 0x15 0x01 0x64>;
				phandle = <0x55>;
			};

			sdmmc-pwr {
				rockchip,pins = <0x01 0x0e 0x00 0x65>;
				phandle = <0x52>;
			};
		};

		sdio {

			sdio-clk {
				rockchip,pins = <0x03 0x00 0x01 0x66>;
				phandle = <0x56>;
			};

			sdio-cmd {
				rockchip,pins = <0x03 0x01 0x01 0x67>;
				phandle = <0x57>;
			};

			sdio-bus4 {
				rockchip,pins = <0x03 0x02 0x01 0x67 0x03 0x03 0x01 0x67 0x03 0x04 0x01 0x67 0x03 0x05 0x01 0x67>;
				phandle = <0x58>;
			};
		};

		flash {

			flash-cs0 {
				rockchip,pins = <0x02 0x06 0x01 0x64>;
				phandle = <0xab>;
			};

			flash-cs1 {
				rockchip,pins = <0x00 0x17 0x01 0x64>;
				phandle = <0xac>;
			};

			flash-cs2 {
				rockchip,pins = <0x01 0x16 0x01 0x64>;
				phandle = <0xad>;
			};

			flash-cs3 {
				rockchip,pins = <0x01 0x17 0x01 0x64>;
				phandle = <0xae>;
			};

			flash-rdy {
				rockchip,pins = <0x02 0x04 0x01 0x64>;
				phandle = <0xaf>;
			};

			flash-ale {
				rockchip,pins = <0x02 0x00 0x01 0x63>;
				phandle = <0xb0>;
			};

			flash-cle {
				rockchip,pins = <0x02 0x01 0x01 0x63>;
				phandle = <0xb1>;
			};

			flash-wrn {
				rockchip,pins = <0x02 0x02 0x01 0x64>;
				phandle = <0xb2>;
			};

			flash-rdn {
				rockchip,pins = <0x02 0x03 0x01 0x64>;
				phandle = <0xb3>;
			};

			flash-bus8 {
				rockchip,pins = <0x01 0x18 0x01 0x64 0x01 0x19 0x01 0x64 0x01 0x1a 0x01 0x64 0x01 0x1b 0x01 0x64 0x01 0x1c 0x01 0x64 0x01 0x1d 0x01 0x64 0x01 0x1e 0x01 0x64 0x01 0x1f 0x01 0x64>;
				phandle = <0xb4>;
			};

			flash-dqs {
				rockchip,pins = <0x02 0x07 0x01 0x64>;
				phandle = <0xb5>;
			};

			flash-wp {
				rockchip,pins = <0x02 0x05 0x01 0x63>;
				phandle = <0xb6>;
			};
		};

		emmc {

			emmc-clk {
				rockchip,pins = <0x02 0x07 0x02 0x64>;
				phandle = <0xb7>;
			};

			emmc-cmd {
				rockchip,pins = <0x01 0x16 0x02 0x64>;
				phandle = <0xb8>;
			};

			emmc-bus8 {
				rockchip,pins = <0x01 0x18 0x02 0x64 0x01 0x19 0x02 0x64 0x01 0x1a 0x02 0x64 0x01 0x1b 0x02 0x64 0x01 0x1c 0x02 0x64 0x01 0x1d 0x02 0x64 0x01 0x1e 0x02 0x64 0x01 0x1f 0x02 0x64>;
				phandle = <0xb9>;
			};

			emmc-pwr {
				rockchip,pins = <0x02 0x05 0x02 0x63>;
				phandle = <0xba>;
			};

			emmc-rst {
				rockchip,pins = <0x01 0x17 0x02 0x64>;
				phandle = <0xbb>;
			};
		};

		gmac {

			rgmii-pins {
				rockchip,pins = <0x02 0x0e 0x01 0x65 0x02 0x0c 0x01 0x65 0x02 0x19 0x01 0x65 0x02 0x13 0x01 0x68 0x02 0x12 0x01 0x68 0x02 0x16 0x01 0x68 0x02 0x17 0x01 0x68 0x02 0x09 0x01 0x68 0x02 0x0d 0x01 0x68 0x02 0x11 0x01 0x65 0x02 0x10 0x01 0x65 0x02 0x15 0x02 0x65 0x02 0x14 0x02 0x65 0x02 0x0b 0x01 0x65 0x02 0x08 0x01 0x65>;
				phandle = <0xbc>;
			};

			rmii-pins {
				rockchip,pins = <0x02 0x0e 0x01 0x65 0x02 0x0c 0x01 0x65 0x02 0x19 0x01 0x65 0x02 0x13 0x01 0x68 0x02 0x12 0x01 0x68 0x02 0x0d 0x01 0x68 0x02 0x11 0x01 0x65 0x02 0x10 0x01 0x65 0x02 0x08 0x01 0x65 0x02 0x0f 0x01 0x65>;
				phandle = <0xbd>;
			};

			phy-pins {
				rockchip,pins = <0x02 0x0e 0x02 0x65 0x02 0x08 0x02 0x65>;
				phandle = <0x61>;
			};
		};

		hdmi {

			hdmi-hpd {
				rockchip,pins = <0x00 0x0f 0x01 0x63>;
				phandle = <0x4e>;
			};

			hdmii2c-xfer {
				rockchip,pins = <0x00 0x06 0x02 0x65 0x00 0x07 0x02 0x65>;
				phandle = <0x4d>;
			};

			hdmi-cec {
				rockchip,pins = <0x00 0x14 0x01 0x65>;
				phandle = <0x4f>;
			};
		};

		i2c0 {

			i2c0-xfer {
				rockchip,pins = <0x00 0x00 0x01 0x65 0x00 0x01 0x01 0x65>;
				phandle = <0x29>;
			};
		};

		i2c1 {

			i2c1-xfer {
				rockchip,pins = <0x00 0x02 0x01 0x65 0x00 0x03 0x01 0x65>;
				phandle = <0x2a>;
			};
		};

		i2c2 {

			i2c2-xfer {
				rockchip,pins = <0x02 0x14 0x01 0x65 0x02 0x15 0x01 0x65>;
				phandle = <0x2b>;
			};
		};

		i2c3 {

			i2c3-xfer {
				rockchip,pins = <0x00 0x06 0x01 0x65 0x00 0x07 0x01 0x65>;
				phandle = <0x2c>;
			};
		};

		tsp {

			tsp-d0 {
				rockchip,pins = <0x02 0x13 0x02 0x65>;
				phandle = <0x11>;
			};

			tsp-d1 {
				rockchip,pins = <0x02 0x12 0x02 0x65>;
				phandle = <0x12>;
			};

			tsp-d2 {
				rockchip,pins = <0x02 0x11 0x02 0x65>;
				phandle = <0x13>;
			};

			tsp-d3 {
				rockchip,pins = <0x02 0x10 0x02 0x65>;
				phandle = <0x14>;
			};

			tsp-d4 {
				rockchip,pins = <0x02 0x19 0x02 0x65>;
				phandle = <0x15>;
			};

			tsp-d5 {
				rockchip,pins = <0x02 0x18 0x02 0x65>;
				phandle = <0x16>;
			};

			tsp-d6 {
				rockchip,pins = <0x02 0x0f 0x02 0x65>;
				phandle = <0x17>;
			};

			tsp-d7 {
				rockchip,pins = <0x02 0x0d 0x02 0x65>;
				phandle = <0x18>;
			};

			tsp-sync {
				rockchip,pins = <0x02 0x0c 0x02 0x65>;
				phandle = <0x19>;
			};

			tsp-clk {
				rockchip,pins = <0x02 0x0b 0x02 0x65>;
				phandle = <0x1a>;
			};

			tsp-fail {
				rockchip,pins = <0x02 0x0a 0x02 0x65>;
				phandle = <0x1b>;
			};

			tsp-valid {
				rockchip,pins = <0x02 0x09 0x02 0x65>;
				phandle = <0x1c>;
			};
		};

		spi-0 {

			spi0-clk {
				rockchip,pins = <0x00 0x09 0x02 0x64>;
				phandle = <0x2d>;
			};

			spi0-cs0 {
				rockchip,pins = <0x00 0x0e 0x02 0x64>;
				phandle = <0x30>;
			};

			spi0-tx {
				rockchip,pins = <0x00 0x0b 0x02 0x64>;
				phandle = <0x2e>;
			};

			spi0-rx {
				rockchip,pins = <0x00 0x0d 0x02 0x64>;
				phandle = <0x2f>;
			};

			spi0-cs1 {
				rockchip,pins = <0x01 0x0c 0x01 0x64>;
				phandle = <0x31>;
			};
		};

		spi-1 {

			spi1-clk {
				rockchip,pins = <0x00 0x17 0x02 0x64>;
				phandle = <0xbe>;
			};

			spi1-cs0 {
				rockchip,pins = <0x02 0x02 0x02 0x64>;
				phandle = <0xbf>;
			};

			spi1-rx {
				rockchip,pins = <0x02 0x00 0x02 0x64>;
				phandle = <0xc0>;
			};

			spi1-tx {
				rockchip,pins = <0x02 0x01 0x02 0x64>;
				phandle = <0xc1>;
			};

			spi1-cs1 {
				rockchip,pins = <0x02 0x03 0x02 0x64>;
				phandle = <0xc2>;
			};
		};

		i2s1 {

			i2s1-bus {
				rockchip,pins = <0x00 0x08 0x01 0x65 0x00 0x09 0x01 0x65 0x00 0x0b 0x01 0x65 0x00 0x0c 0x01 0x65 0x00 0x0d 0x01 0x65 0x00 0x0e 0x01 0x65 0x01 0x02 0x02 0x65 0x01 0x04 0x02 0x65 0x01 0x05 0x02 0x65>;
				phandle = <0x0f>;
			};
		};

		pwm0 {

			pwm0-pin {
				rockchip,pins = <0x03 0x15 0x01 0x65>;
				phandle = <0x32>;
			};

			pwm0-pin-pull-down {
				rockchip,pins = <0x03 0x15 0x01 0x63>;
				phandle = <0xc3>;
			};
		};

		pwm1 {

			pwm1-pin {
				rockchip,pins = <0x00 0x1e 0x02 0x65>;
				phandle = <0xc4>;
			};

			pwm1-pin-pull-down {
				rockchip,pins = <0x00 0x1e 0x02 0x63>;
				phandle = <0x33>;
			};
		};

		pwm2 {

			pwm2-pin {
				rockchip,pins = <0x01 0x0c 0x02 0x65>;
				phandle = <0xc5>;
			};

			pwm2-pin-pull-up {
				rockchip,pins = <0x01 0x0c 0x02 0x64>;
				phandle = <0x34>;
			};
		};

		pwm3 {

			pwm3-pin {
				rockchip,pins = <0x01 0x0b 0x02 0x65>;
				phandle = <0x35>;
			};

			pwm3-pin-pull-down {
				rockchip,pins = <0x01 0x0b 0x02 0x63>;
				phandle = <0xc6>;
			};
		};

		spdif {

			spdif-tx {
				rockchip,pins = <0x03 0x1f 0x02 0x65>;
				phandle = <0x10>;
			};
		};

		tsadc {

			otp-gpio {
				rockchip,pins = <0x00 0x18 0x00 0x65>;
				phandle = <0x3d>;
			};

			otp-out {
				rockchip,pins = <0x00 0x18 0x02 0x65>;
				phandle = <0x3e>;
			};
		};

		uart0 {

			uart0-xfer {
				rockchip,pins = <0x02 0x1a 0x01 0x65 0x02 0x1b 0x01 0x65>;
				phandle = <0x24>;
			};

			uart0-cts {
				rockchip,pins = <0x02 0x1d 0x01 0x65>;
				phandle = <0x25>;
			};

			uart0-rts {
				rockchip,pins = <0x00 0x11 0x01 0x65>;
				phandle = <0x26>;
			};
		};

		uart1 {

			uart1-xfer {
				rockchip,pins = <0x01 0x09 0x01 0x65 0x01 0x0a 0x01 0x65>;
				phandle = <0x27>;
			};

			uart1-cts {
				rockchip,pins = <0x01 0x08 0x01 0x65>;
				phandle = <0xc7>;
			};

			uart1-rts {
				rockchip,pins = <0x01 0x0b 0x01 0x65>;
				phandle = <0xc8>;
			};
		};

		uart1-1 {

			uart11-xfer {
				rockchip,pins = <0x03 0x0e 0x01 0x64 0x03 0x0d 0x01 0x65>;
				phandle = <0xc9>;
			};

			uart11-cts {
				rockchip,pins = <0x03 0x07 0x01 0x65>;
				phandle = <0xca>;
			};

			uart11-rts {
				rockchip,pins = <0x03 0x06 0x01 0x65>;
				phandle = <0xcb>;
			};

			uart11-rts-gpio {
				rockchip,pins = <0x03 0x06 0x00 0x65>;
				phandle = <0xcc>;
			};
		};

		uart2 {

			uart2-xfer {
				rockchip,pins = <0x01 0x12 0x02 0x64 0x01 0x13 0x02 0x65>;
				phandle = <0xcd>;
			};

			uart2-cts {
				rockchip,pins = <0x00 0x19 0x01 0x65>;
				phandle = <0xce>;
			};

			uart2-rts {
				rockchip,pins = <0x00 0x18 0x01 0x65>;
				phandle = <0xcf>;
			};
		};

		uart2-1 {

			uart21-xfer {
				rockchip,pins = <0x01 0x0a 0x02 0x64 0x01 0x09 0x02 0x65>;
				phandle = <0x28>;
			};
		};

		keys {

			pwr-key {
				rockchip,pins = <0x03 0x17 0x00 0x64>;
				phandle = <0xd0>;
			};
		};

		sdio-pwrseq {

			wifi-enable-h {
				rockchip,pins = <0x02 0x1a 0x00 0x65>;
				phandle = <0x77>;
			};
		};

		usb {

			host-vbus-drv {
				rockchip,pins = <0x03 0x14 0x00 0x65>;
				phandle = <0x71>;
			};

			otg-vbus-drv {
				rockchip,pins = <0x03 0x16 0x00 0x65>;
				phandle = <0x72>;
			};
		};

		ir {

			ir-int {
				rockchip,pins = <0x01 0x0b 0x00 0x65>;
				phandle = <0x75>;
			};
		};

		pcfg-pull-up-12ma {
			drive-strength = <0x0c>;
			bias-pull-up;
			phandle = <0xd1>;
		};

		pcfg-pull-down-12ma {
			drive-strength = <0x0c>;
			bias-pull-down;
			phandle = <0xd2>;
		};

		pcfg-pull-none-12ma {
			drive-strength = <0x0c>;
			bias-disable;
			phandle = <0xd3>;
		};

		pcfg-pull-up-8ma {
			drive-strength = <0x08>;
			bias-pull-up;
			phandle = <0xd4>;
		};

		pcfg-pull-down-8ma {
			drive-strength = <0x08>;
			bias-pull-down;
			phandle = <0xd5>;
		};

		pcfg-pull-none-8ma {
			drive-strength = <0x08>;
			bias-disable;
			phandle = <0xd6>;
		};

		pcfg-pull-up-2ma {
			drive-strength = <0x02>;
			bias-pull-up;
			phandle = <0x67>;
		};

		pcfg-pull-down-2ma {
			drive-strength = <0x02>;
			bias-pull-down;
			phandle = <0x66>;
		};

		pcfg-pull-none-2ma {
			drive-strength = <0x02>;
			bias-disable;
			phandle = <0xd7>;
		};

		gpio {

			gpio-led-working {
				rockchip,pins = <0x03 0x15 0x00 0x65>;
				phandle = <0x76>;
			};
		};
	};

	rockchip-suspend {
		compatible = "rockchip,pm-rk322x";
		status = "okay";
		rockchip,virtual-poweroff = <0x01>;
		rockchip,sleep-mode-config = <0x10042>;
		phandle = <0xd8>;
	};

	memory@60000000 {
		device_type = "memory";
		reg = <0x60000000 0x40000000>;
	};

	bus_intmem@10080000 {
		compatible = "mmio-sram";
		reg = <0x10080000 0x9000>;
		#address-cells = <0x01>;
		#size-cells = <0x01>;
		ranges = <0x00 0x10080000 0x9000>;

		smp-sram@0 {
			compatible = "rockchip,rk3066-smp-sram";
			reg = <0x00 0x10>;
		};

		ddr-sram@1000 {
			compatible = "rockchip,rk322x-ddr-sram";
			reg = <0x1000 0x8000>;
			phandle = <0xd9>;
		};
	};

	fiq-debugger {
		compatible = "rockchip,fiq-debugger";
		interrupts = <0x00 0x51 0x04>;
		rockchip,serial-id = <0x02>;
		rockchip,signal-irq = <0x9f>;
		rockchip,wake-irq = <0x00>;
		rockchip,irq-mode-enable = <0x00>;
		rockchip,baudrate = <0x1c200>;
		pinctrl-names = "default";
		pinctrl-0 = <0x28>;
		status = "disabled";
	};

	reserved-memory {
		#address-cells = <0x01>;
		#size-cells = <0x01>;
		ranges;

		ramoops@62e00000 {
			reg = <0x62e00000 0xf0000>;
			phandle = <0x69>;
		};

		trust@68400000 {
			reg = <0x68400000 0x2000000>;
			no-map;
			phandle = <0xda>;
		};
	};

	ramoops {
		compatible = "ramoops";
		record-size = <0x00 0x20000>;
		console-size = <0x00 0x80000>;
		ftrace-size = <0x00 0x00>;
		pmsg-size = <0x00 0x50000>;
		memory-region = <0x69>;
	};

	psci {
		compatible = "arm,psci-1.0";
		method = "smc";
	};

	sound {
		status = "okay";
		compatible = "simple-audio-card";
		simple-audio-card,format = "i2s";
		simple-audio-card,mclk-fs = <0x100>;
		simple-audio-card,name = "ANALOG";

		simple-audio-card,cpu {
			sound-dai = <0x6a>;
		};

		simple-audio-card,codec {
			sound-dai = <0x6b>;
		};
	};

	hdmi-sound {
		status = "okay";
		compatible = "simple-audio-card";
		simple-audio-card,format = "i2s";
		simple-audio-card,mclk-fs = <0x80>;
		simple-audio-card,name = "DW-I2S-HDMI";
		phandle = <0xdb>;

		simple-audio-card,cpu {
			sound-dai = <0x6c>;
		};

		simple-audio-card,codec {
			sound-dai = <0x6d>;
		};
	};

	regulators {
		compatible = "simple-bus";
		#address-cells = <0x01>;
		#size-cells = <0x00>;

		regulator@0 {
			compatible = "regulator-fixed";
			regulator-name = "vccio_1v8";
			regulator-min-microvolt = <0x1b7740>;
			regulator-max-microvolt = <0x1b7740>;
			regulator-always-on;
			phandle = <0x1e>;
		};

		regulator@1 {
			compatible = "regulator-fixed";
			regulator-name = "vccio_3v3";
			regulator-min-microvolt = <0x325aa0>;
			regulator-max-microvolt = <0x325aa0>;
			regulator-always-on;
			phandle = <0x1d>;
		};
	};

	spdif-out {
		status = "okay";
		compatible = "linux,spdif-dit";
		#sound-dai-cells = <0x00>;
		phandle = <0x6f>;
	};

	spdif-sound {
		status = "okay";
		compatible = "simple-audio-card";
		simple-audio-card,name = "SPDIF";

		simple-audio-card,cpu {
			sound-dai = <0x6e>;
		};

		simple-audio-card,codec {
			sound-dai = <0x6f>;
		};
	};

	vcc-host-regulator {
		compatible = "regulator-fixed";
		enable-active-high;
		gpio = <0x70 0x14 0x00>;
		pinctrl-names = "default";
		pinctrl-0 = <0x71>;
		regulator-name = "vcc_host";
		regulator-always-on;
		regulator-boot-on;
		phandle = <0x20>;
	};

	otg-vbus-regulator {
		compatible = "regulator-fixed";
		gpio = <0x70 0x16 0x00>;
		pinctrl-names = "default";
		pinctrl-0 = <0x72>;
		regulator-name = "vcc_otg_vbus";
		regulator-min-microvolt = <0x4c4b40>;
		regulator-max-microvolt = <0x4c4b40>;
		enable-active-high;
		phandle = <0x1f>;
	};

	vcc-phy-regulator {
		compatible = "regulator-fixed";
		enable-active-high;
		regulator-name = "vcc_phy";
		regulator-min-microvolt = <0x1b7740>;
		regulator-max-microvolt = <0x1b7740>;
		regulator-always-on;
		regulator-boot-on;
		phandle = <0x60>;
	};

	vdd-arm-regulator {
		compatible = "pwm-regulator";
		rockchip,pwm_id = <0x01>;
		rockchip,pwm_voltage = <0x10c8e0>;
		pwms = <0x73 0x00 0x1388 0x01>;
		regulator-name = "vdd_arm";
		regulator-min-microvolt = <0xe7ef0>;
		regulator-max-microvolt = <0x155cc0>;
		regulator-ramp-delay = <0x30d4>;
		regulator-settling-time-up-us = <0xfa>;
		regulator-always-on;
		regulator-boot-on;
		phandle = <0x04>;
	};

	vdd-log-regulator {
		compatible = "pwm-regulator";
		rockchip,pwm_id = <0x02>;
		rockchip,pwm_voltage = <0x124f80>;
		pwms = <0x74 0x00 0x1388 0x01>;
		regulator-name = "vdd_log";
		regulator-min-microvolt = <0xf4240>;
		regulator-max-microvolt = <0x13d620>;
		regulator-ramp-delay = <0x30d4>;
		regulator-settling-time-up-us = <0xfa>;
		regulator-always-on;
		regulator-boot-on;
		phandle = <0x0c>;
	};

	ir-receiver {
		compatible = "gpio-ir-receiver";
		gpios = <0x3f 0x0b 0x01>;
		linux,rc-map-name = "rc-rktvbox";
		pinctrl-0 = <0x75>;
		pinctrl-names = "default";
		phandle = <0xdc>;
	};

	gpio-leds {
		compatible = "gpio-leds";
		phandle = <0xdd>;

		working {
			pinctrl-names = "default";
			pinctrl-0 = <0x76>;
			gpios = <0x70 0x15 0x01>;
			label = "working";
			default-state = "on";
			linux,default-trigger = "timer";
		};
	};

	gpio-keys {
		compatible = "gpio-keys";
		#address-cells = <0x01>;
		#size-cells = <0x00>;
		phandle = <0xde>;
	};

	sdio-pwrseq {
		compatible = "mmc-pwrseq-simple";
		pinctrl-names = "default";
		pinctrl-0 = <0x77>;
		reset-gpios = <0x62 0x1a 0x01>;
		phandle = <0x59>;
	};

	__symbols__ {
		dram_timing = "/dram_timing";
		cpu0 = "/cpus/cpu@f00";
		cpu1 = "/cpus/cpu@f01";
		cpu2 = "/cpus/cpu@f02";
		cpu3 = "/cpus/cpu@f03";
		cpu0_opp_table = "/opp_table0";
		pdma = "/amba/pdma@110f0000";
		dmc = "/dmc";
		ddr_power_model = "/dmc/ddr_power_model";
		dmc_opp_table = "/dmc-opp-table";
		xin24m = "/oscillator";
		rng = "/rng@100a0000";
		i2s1 = "/i2s1@100b0000";
		i2s0 = "/i2s0@100c0000";
		spdif = "/spdif@100d0000";
		i2s2 = "/i2s2@100e0000";
		tsp = "/tsp@100f0000";
		grf = "/syscon@11000000";
		io_domains = "/syscon@11000000/io-domains";
		reboot_mode = "/syscon@11000000/reboot-mode";
		u2phy0 = "/syscon@11000000/usb2-phy@760";
		u2phy0_otg = "/syscon@11000000/usb2-phy@760/otg-port";
		u2phy0_host = "/syscon@11000000/usb2-phy@760/host-port";
		u2phy1 = "/syscon@11000000/usb2-phy@800";
		u2phy1_otg = "/syscon@11000000/usb2-phy@800/otg-port";
		u2phy1_host = "/syscon@11000000/usb2-phy@800/host-port";
		power = "/syscon@11000000/power-controller";
		uart0 = "/serial@11010000";
		uart1 = "/serial@11020000";
		uart2 = "/serial@11030000";
		efuse = "/efuse@11040000";
		efuse_id = "/efuse@11040000/id@7";
		cpu_leakage = "/efuse@11040000/cpu_leakage@17";
		logic_leakage = "/efuse@11040000/logic-leakage@19";
		hdmi_phy_flag = "/efuse@11040000/hdmi_phy_flag@1d";
		tve_dac = "/efuse@11040000/tve_dac@1d";
		i2c0 = "/i2c@11050000";
		i2c1 = "/i2c@11060000";
		i2c2 = "/i2c@11070000";
		i2c3 = "/i2c@11080000";
		spi0 = "/spi@11090000";
		wdt = "/watchdog@110a0000";
		pwm0 = "/pwm@110b0000";
		pwm1 = "/pwm@110b0010";
		pwm2 = "/pwm@110b0020";
		pwm3 = "/pwm@110b0030";
		timer = "/timer@110c0000";
		cru = "/clock-controller@110e0000";
		thermal_zones = "/thermal-zones";
		soc_thermal = "/thermal-zones/soc-thermal";
		threshold = "/thermal-zones/soc-thermal/trips/trip-point@0";
		target = "/thermal-zones/soc-thermal/trips/trip-point@1";
		soc_crit = "/thermal-zones/soc-thermal/trips/soc-crit";
		tsadc = "/tsadc@11150000";
		codec = "/codec@12010000";
		hdmi_phy = "/hdmi-phy@12030000";
		gpu = "/gpu@0x20001000";
		gpu_power_model = "/gpu@0x20001000/power_model";
		gpu_opp_table = "/opp-table2";
		vpu_service = "/vpu-service@20020000";
		vpu_mmu = "/iommu@20020800";
		rkvdec = "/rkvdec@20030000";
		vcodec_power_model = "/rkvdec@20030000/vcodec_power_model";
		rkvdec_opp_table = "/rkvdec-opp-table";
		rkvdec_mmu = "/iommu@20030480";
		vop = "/vop@20050000";
		vop_out = "/vop@20050000/port";
		vop_out_hdmi = "/vop@20050000/port/endpoint@0";
		vop_out_tve = "/vop@20050000/port/endpoint@1";
		vop_mmu = "/iommu@20050300";
		rk_rga = "/rk_rga@20060000";
		iep = "/iep@20070000";
		iep_mmu = "/iommu@20070800";
		display_subsystem = "/display-subsystem";
		route_hdmi = "/display-subsystem/route-hdmi";
		route_tve = "/display-subsystem/route-tve";
		hdmi = "/hdmi@200a0000";
		hdmi_in = "/hdmi@200a0000/ports/port";
		hdmi_in_vop = "/hdmi@200a0000/ports/port/endpoint@0";
		tve = "/tve@20053e00";
		tve_in = "/tve@20053e00/ports/port";
		tve_in_vop = "/tve@20053e00/ports/port/endpoint@0";
		sdmmc = "/dwmmc@30000000";
		sdio = "/dwmmc@30010000";
		emmc = "/dwmmc@30020000";
		nandc = "/nandc@30030000";
		usb_otg = "/usb@30040000";
		usb_host0_ehci = "/usb@30080000";
		usb_host0_ohci = "/usb@300a0000";
		usb_host1_ehci = "/usb@300c0000";
		usb_host1_ohci = "/usb@300e0000";
		usb_host2_ehci = "/usb@30100000";
		usb_host2_ohci = "/usb@30120000";
		gmac = "/ethernet@30200000";
		qos_vpu = "/qos@31040000";
		qos_rkvdec_r = "/qos@31070000";
		qos_rkvdec_w = "/qos@31070080";
		gic = "/interrupt-controller@32010000";
		rockchip_system_monitor = "/rockchip-system-monitor";
		pinctrl = "/pinctrl";
		gpio0 = "/pinctrl/gpio0@11110000";
		gpio1 = "/pinctrl/gpio1@11120000";
		gpio2 = "/pinctrl/gpio2@11130000";
		gpio3 = "/pinctrl/gpio3@11140000";
		pcfg_pull_up = "/pinctrl/pcfg-pull-up";
		pcfg_pull_down = "/pinctrl/pcfg-pull-down";
		pcfg_pull_none = "/pinctrl/pcfg-pull-none";
		pcfg_pull_none_drv_12ma = "/pinctrl/pcfg-pull-none-drv-12ma";
		sdmmc_clk = "/pinctrl/sdmmc/sdmmc-clk";
		sdmmc_cmd = "/pinctrl/sdmmc/sdmmc-cmd";
		sdmmc_bus4 = "/pinctrl/sdmmc/sdmmc-bus4";
		sdmmc_pwr = "/pinctrl/sdmmc/sdmmc-pwr";
		sdio_clk = "/pinctrl/sdio/sdio-clk";
		sdio_cmd = "/pinctrl/sdio/sdio-cmd";
		sdio_bus4 = "/pinctrl/sdio/sdio-bus4";
		flash_cs0 = "/pinctrl/flash/flash-cs0";
		flash_cs1 = "/pinctrl/flash/flash-cs1";
		flash_cs2 = "/pinctrl/flash/flash-cs2";
		flash_cs3 = "/pinctrl/flash/flash-cs3";
		flash_rdy = "/pinctrl/flash/flash-rdy";
		flash_ale = "/pinctrl/flash/flash-ale";
		flash_cle = "/pinctrl/flash/flash-cle";
		flash_wrn = "/pinctrl/flash/flash-wrn";
		flash_rdn = "/pinctrl/flash/flash-rdn";
		flash_bus8 = "/pinctrl/flash/flash-bus8";
		flash_dqs = "/pinctrl/flash/flash-dqs";
		flash_wp = "/pinctrl/flash/flash-wp";
		emmc_clk = "/pinctrl/emmc/emmc-clk";
		emmc_cmd = "/pinctrl/emmc/emmc-cmd";
		emmc_bus8 = "/pinctrl/emmc/emmc-bus8";
		emmc_pwr = "/pinctrl/emmc/emmc-pwr";
		emmc_rst = "/pinctrl/emmc/emmc-rst";
		rgmii_pins = "/pinctrl/gmac/rgmii-pins";
		rmii_pins = "/pinctrl/gmac/rmii-pins";
		phy_pins = "/pinctrl/gmac/phy-pins";
		hdmi_hpd = "/pinctrl/hdmi/hdmi-hpd";
		hdmii2c_xfer = "/pinctrl/hdmi/hdmii2c-xfer";
		hdmi_cec = "/pinctrl/hdmi/hdmi-cec";
		i2c0_xfer = "/pinctrl/i2c0/i2c0-xfer";
		i2c1_xfer = "/pinctrl/i2c1/i2c1-xfer";
		i2c2_xfer = "/pinctrl/i2c2/i2c2-xfer";
		i2c3_xfer = "/pinctrl/i2c3/i2c3-xfer";
		tsp_d0 = "/pinctrl/tsp/tsp-d0";
		tsp_d1 = "/pinctrl/tsp/tsp-d1";
		tsp_d2 = "/pinctrl/tsp/tsp-d2";
		tsp_d3 = "/pinctrl/tsp/tsp-d3";
		tsp_d4 = "/pinctrl/tsp/tsp-d4";
		tsp_d5 = "/pinctrl/tsp/tsp-d5";
		tsp_d6 = "/pinctrl/tsp/tsp-d6";
		tsp_d7 = "/pinctrl/tsp/tsp-d7";
		tsp_sync = "/pinctrl/tsp/tsp-sync";
		tsp_clk = "/pinctrl/tsp/tsp-clk";
		tsp_fail = "/pinctrl/tsp/tsp-fail";
		tsp_valid = "/pinctrl/tsp/tsp-valid";
		spi0_clk = "/pinctrl/spi-0/spi0-clk";
		spi0_cs0 = "/pinctrl/spi-0/spi0-cs0";
		spi0_tx = "/pinctrl/spi-0/spi0-tx";
		spi0_rx = "/pinctrl/spi-0/spi0-rx";
		spi0_cs1 = "/pinctrl/spi-0/spi0-cs1";
		spi1_clk = "/pinctrl/spi-1/spi1-clk";
		spi1_cs0 = "/pinctrl/spi-1/spi1-cs0";
		spi1_rx = "/pinctrl/spi-1/spi1-rx";
		spi1_tx = "/pinctrl/spi-1/spi1-tx";
		spi1_cs1 = "/pinctrl/spi-1/spi1-cs1";
		i2s1_bus = "/pinctrl/i2s1/i2s1-bus";
		pwm0_pin = "/pinctrl/pwm0/pwm0-pin";
		pwm0_pin_pull_down = "/pinctrl/pwm0/pwm0-pin-pull-down";
		pwm1_pin = "/pinctrl/pwm1/pwm1-pin";
		pwm1_pin_pull_down = "/pinctrl/pwm1/pwm1-pin-pull-down";
		pwm2_pin = "/pinctrl/pwm2/pwm2-pin";
		pwm2_pin_pull_up = "/pinctrl/pwm2/pwm2-pin-pull-up";
		pwm3_pin = "/pinctrl/pwm3/pwm3-pin";
		pwm3_pin_pull_down = "/pinctrl/pwm3/pwm3-pin-pull-down";
		spdif_tx = "/pinctrl/spdif/spdif-tx";
		otp_gpio = "/pinctrl/tsadc/otp-gpio";
		otp_out = "/pinctrl/tsadc/otp-out";
		uart0_xfer = "/pinctrl/uart0/uart0-xfer";
		uart0_cts = "/pinctrl/uart0/uart0-cts";
		uart0_rts = "/pinctrl/uart0/uart0-rts";
		uart1_xfer = "/pinctrl/uart1/uart1-xfer";
		uart1_cts = "/pinctrl/uart1/uart1-cts";
		uart1_rts = "/pinctrl/uart1/uart1-rts";
		uart11_xfer = "/pinctrl/uart1-1/uart11-xfer";
		uart11_cts = "/pinctrl/uart1-1/uart11-cts";
		uart11_rts = "/pinctrl/uart1-1/uart11-rts";
		uart11_rts_gpio = "/pinctrl/uart1-1/uart11-rts-gpio";
		uart2_xfer = "/pinctrl/uart2/uart2-xfer";
		uart2_cts = "/pinctrl/uart2/uart2-cts";
		uart2_rts = "/pinctrl/uart2/uart2-rts";
		uart21_xfer = "/pinctrl/uart2-1/uart21-xfer";
		pwr_key = "/pinctrl/keys/pwr-key";
		wifi_enable_h = "/pinctrl/sdio-pwrseq/wifi-enable-h";
		host_vbus_drv = "/pinctrl/usb/host-vbus-drv";
		otg_vbus_drv = "/pinctrl/usb/otg-vbus-drv";
		ir_int = "/pinctrl/ir/ir-int";
		pcfg_pull_up_12ma = "/pinctrl/pcfg-pull-up-12ma";
		pcfg_pull_down_12ma = "/pinctrl/pcfg-pull-down-12ma";
		pcfg_pull_none_12ma = "/pinctrl/pcfg-pull-none-12ma";
		pcfg_pull_up_8ma = "/pinctrl/pcfg-pull-up-8ma";
		pcfg_pull_down_8ma = "/pinctrl/pcfg-pull-down-8ma";
		pcfg_pull_none_8ma = "/pinctrl/pcfg-pull-none-8ma";
		pcfg_pull_up_2ma = "/pinctrl/pcfg-pull-up-2ma";
		pcfg_pull_down_2ma = "/pinctrl/pcfg-pull-down-2ma";
		pcfg_pull_none_2ma = "/pinctrl/pcfg-pull-none-2ma";
		gpio_led_working = "/pinctrl/gpio/gpio-led-working";
		rockchip_suspend = "/rockchip-suspend";
		ddr_sram = "/bus_intmem@10080000/ddr-sram@1000";
		ramoops_mem = "/reserved-memory/ramoops@62e00000";
		trust_reserved = "/reserved-memory/trust@68400000";
		hdmi_sound = "/hdmi-sound";
		vccio_1v8_reg = "/regulators/regulator@0";
		vccio_3v3_reg = "/regulators/regulator@1";
		spdif_out = "/spdif-out";
		vcc_host = "/vcc-host-regulator";
		vcc_otg_vbus = "/otg-vbus-regulator";
		vcc_phy = "/vcc-phy-regulator";
		vdd_arm = "/vdd-arm-regulator";
		vdd_log = "/vdd-log-regulator";
		ir_receiver = "/ir-receiver";
		gpio_leds = "/gpio-leds";
		gpio_keys = "/gpio-keys";
		sdio_pwrseq = "/sdio-pwrseq";
	};
};
